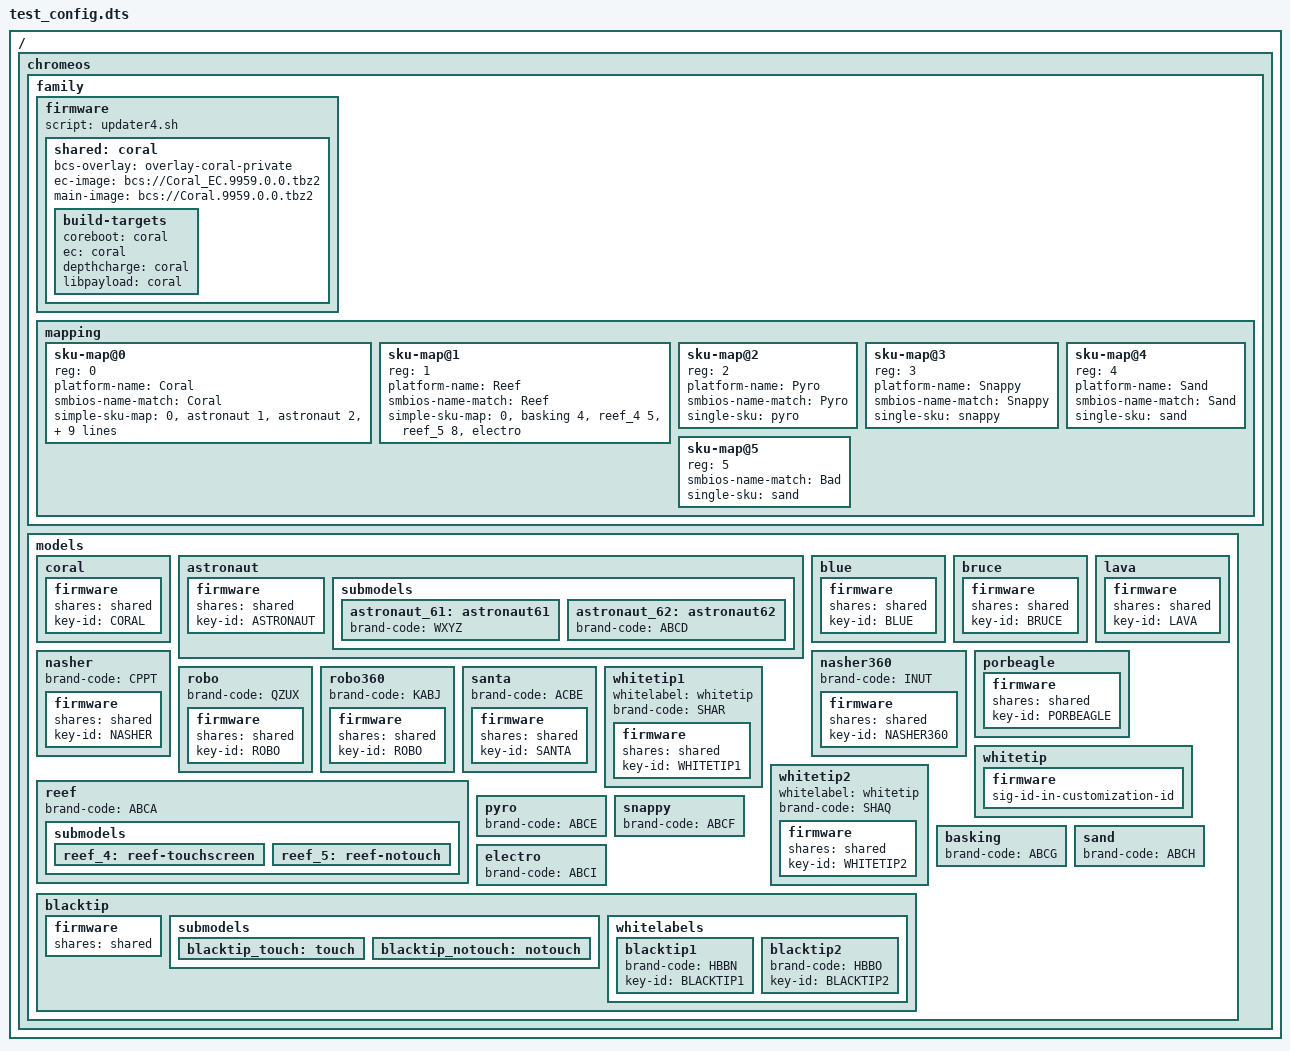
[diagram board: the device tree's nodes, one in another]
/*
 * Copyright 2017 The Chromium OS Authors. All rights reserved.
 *
 * Use of this source code is governed by a BSD-style license that can be
 * found in the LICENSE file.
 */

/dts-v1/;

/ {
	chromeos {
		family: family {
		};

		models: models {
		};
	};
};

&family {
/*
 * NOTE: In order to pin firmware versions for specific models, see:
 * https://chromium.googlesource.com/chromiumos/platform2/+/master/chromeos-config/README.md
 */
	firmware {
		script = "updater4.sh";
		shared: coral {
			bcs-overlay = "overlay-coral-private";
			ec-image = "bcs://Coral_EC.9959.0.0.tbz2";
			main-image = "bcs://Coral.9959.0.0.tbz2";
			build-targets {
				coreboot = "coral";
				ec = "coral";
				depthcharge = "coral";
				libpayload = "coral";
			};
		};
	};

	mapping {
		#address-cells = <1>;
		#size-cells = <0>;
		sku-map@0 {
			reg = <0>;
			platform-name = "Coral";
			smbios-name-match = "Coral";
			/*
			 * This is just for testing only. It is not correct for
			 * actual use with coral.
			 */
			simple-sku-map = < 0 &astronaut
				1 &astronaut
				2 &santa
				3 &santa
				4 &lava
				5 &lava
				6 &blue
				7 &blue
				8 &bruce
				9 &lava
				10 &lava
				26 &porbeagle
				27 &porbeagle
				61 &astronaut_61
				62 &astronaut_62
				70 &robo
				71 &robo360
				78 &whitetip
				82 &whitetip2
				83 &blacktip
				84 &blacktip_touch
				85 &blacktip_notouch
				160 &nasher
				161 &nasher
				162 &nasher
				163 &nasher360
				164 &nasher360
				165 &nasher360
				166 &nasher360 >;
		};
		sku-map@1 {
			reg = <1>;
			platform-name = "Reef";
			smbios-name-match = "Reef";
			/* This is an example! It does not match any real family */
			simple-sku-map = <
				0 &basking
				4 &reef_4
				5 &reef_5
				8 &electro>;
		};
		sku-map@2 {
			reg = <2>;
			platform-name = "Pyro";
			smbios-name-match = "Pyro";
			single-sku = <&pyro>;
		};
		sku-map@3 {
			reg = <3>;
			platform-name = "Snappy";
			smbios-name-match = "Snappy";
			single-sku = <&snappy>;
		};
		sku-map@4 {
			reg = <4>;
			platform-name = "Sand";
			smbios-name-match = "Sand";
			single-sku = <&sand>;
		};
		sku-map@5 {
			/* Missing platform-name */
			reg = <5>;
			smbios-name-match = "Bad";
			single-sku = <&sand>;
		};
	};
};

&models {
	coral {
		firmware {
			shares = < &shared >;
			key-id = "CORAL";
		};
	};

	astronaut: astronaut {
		firmware {
			shares = < &shared >;
			key-id = "ASTRONAUT";
		};
		submodels {
			astronaut_61: astronaut61 {
				brand-code = "WXYZ";
			};

			astronaut_62: astronaut62 {
				brand-code = "ABCD";
			};
		};
	};

	blue: blue {
		firmware {
			shares = < &shared >;
			key-id = "BLUE";
		};
	};

	bruce: bruce {
		firmware {
			shares = < &shared >;
			key-id = "BRUCE";
		};
	};

	lava: lava {
		firmware {
			shares = < &shared >;
			key-id = "LAVA";
		};
	};

	nasher: nasher {
		brand-code = "CPPT";
		firmware {
			shares = < &shared >;
			key-id = "NASHER";
		};
	};

	nasher360: nasher360 {
		brand-code = "INUT";
		firmware {
			shares = < &shared >;
			key-id = "NASHER360";
		};
	};

	porbeagle: porbeagle {
		firmware {
			shares = < &shared >;
			key-id = "PORBEAGLE";
		};
	};

	robo: robo {
		brand-code = "QZUX";
		firmware {
			shares = < &shared >;
			key-id = "ROBO";
		};
	};

	robo360: robo360 {
		brand-code = "KABJ";
		firmware {
			shares = < &shared >;
			/**
			 * TODO(b:65260329): add robo360 root key for signing and correct
			 *                   model.dtsi.
			 */
			key-id = "ROBO";
		};
	};

	santa: santa {
		brand-code = "ACBE";
		firmware {
			shares = < &shared >;
			key-id = "SANTA";
		};
	};

	whitetip: whitetip {
		firmware {
			sig-id-in-customization-id;
		};
	};

	whitetip1: whitetip1 {
		whitelabel = <&whitetip>;
		brand-code = "SHAR";
		firmware {
			shares = < &shared >;
			key-id = "WHITETIP1";
		};
	};

	whitetip2: whitetip2 {
		whitelabel = <&whitetip>;
		brand-code = "SHAQ";
		firmware {
			shares = < &shared >;
			key-id = "WHITETIP2";
		};
	};

	reef: reef {
		brand-code = "ABCA";
		submodels {
			reef_4: reef-touchscreen {
			};
			reef_5: reef-notouch {
			};
		};
	};
	pyro: pyro {
		brand-code = "ABCE";
	};

	snappy: snappy {
		brand-code = "ABCF";
	};

	basking: basking {
		brand-code = "ABCG";
	};

	sand: sand {
		brand-code = "ABCH";
	};

	electro: electro {
		brand-code = "ABCI";
	};

	/* Whitelabel model */
	blacktip: blacktip {
		firmware {
			shares = <&shared>;
		};
		submodels {
			blacktip_touch: touch {
			};
			blacktip_notouch: notouch {
			};
		};
		whitelabels {
			blacktip1 {
				brand-code = "HBBN";
				key-id = "BLACKTIP1";
			};
			blacktip2 {
				brand-code = "HBBO";
				key-id = "BLACKTIP2";
			};
		};
	};
};
